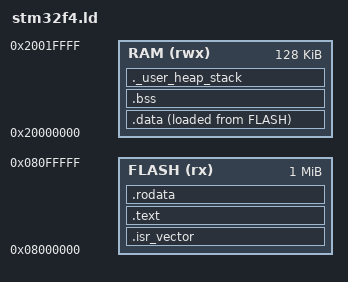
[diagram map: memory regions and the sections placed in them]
/* Linker script for STM32F4 - Fixed for semihosting */
MEMORY
{
  FLASH (rx) : ORIGIN = 0x08000000, LENGTH = 1024K
  RAM (rwx)  : ORIGIN = 0x20000000, LENGTH = 128K
}

ENTRY(Reset_Handler)

SECTIONS
{
  /* The vector table goes first into FLASH */
  .isr_vector :
  {
    . = ALIGN(4);
    KEEP(*(.isr_vector))
    . = ALIGN(4);
  } >FLASH

  /* The program code and other data goes into FLASH */
  .text :
  {
    . = ALIGN(4);
    *(.text)
    *(.text*)
    . = ALIGN(4);
    _etext = .;
  } >FLASH

  /* Constant data goes into FLASH */
  .rodata :
  {
    . = ALIGN(4);
    *(.rodata)
    *(.rodata*)
    . = ALIGN(4);
  } >FLASH

  /* Initialized data goes into RAM */
  .data :
  {
    . = ALIGN(4);
    _sdata = .;
    *(.data)
    *(.data*)
    . = ALIGN(4);
    _edata = .;
  } >RAM AT> FLASH

  /* Uninitialized data goes into RAM */
  .bss :
  {
    . = ALIGN(4);
    _sbss = .;
    __bss_start__ = _sbss;  /* Add this alias */
    *(.bss)
    *(.bss*)
    *(COMMON)
    . = ALIGN(4);
    _ebss = .;
    __bss_end__ = _ebss;    /* Add this alias */
    __end__ = .;            /* Add this symbol */
    end = .;                /* Add this symbol */
  } >RAM

  /* Stack and heap */
  ._user_heap_stack :
  {
    . = ALIGN(8);
    PROVIDE ( end = . );
    PROVIDE ( _end = . );
    . = . + 0x1000; /* Heap */
    . = . + 0x1000; /* Stack */
    . = ALIGN(8);
  } >RAM

  /* Top of stack */
  _estack = ORIGIN(RAM) + LENGTH(RAM);

  /DISCARD/ :
  {
    libc.a ( * )
    libm.a ( * )
    libgcc.a ( * )
  }
}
